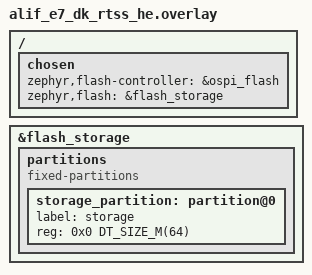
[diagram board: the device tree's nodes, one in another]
/*
 * Copyright (c) 2024 Alif Semiconductor.
 * SPDX-License-Identifier: Apache-2.0
 */

/delete-node/ &mram_flash;

/ {
	chosen {
		zephyr,flash-controller = &ospi_flash;
		zephyr,flash = &flash_storage;

		/delete-property/ zephyr,code-partition;
	};
};

&flash_storage {
	partitions {
		#address-cells = <1>;
		#size-cells = <1>;
		compatible = "fixed-partitions";

		/* Set 64MB of storage flash */
		storage_partition: partition@0 {
			label = "storage";
			reg = <0x0 DT_SIZE_M(64)>;
		};
	};
};
